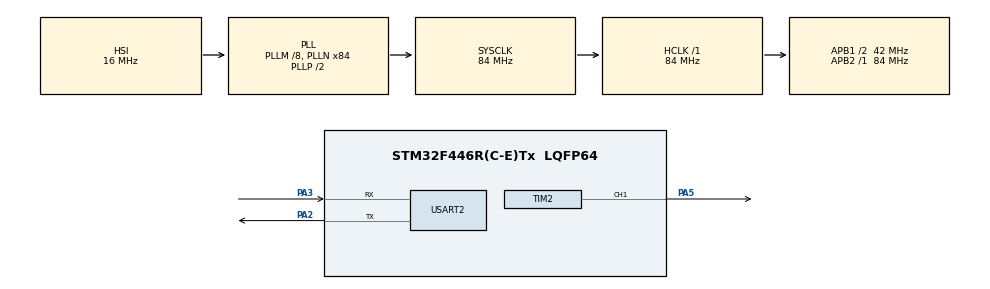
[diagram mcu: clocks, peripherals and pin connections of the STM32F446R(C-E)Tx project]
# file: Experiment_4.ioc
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Mcu.Family=STM32F4
Mcu.Name=STM32F446R(C-E)Tx
Mcu.Package=LQFP64
NVIC.PriorityGroup=NVIC_PRIORITYGROUP_4
PA2.Mode=Asynchronous
PA2.Signal=USART2_TX
PA3.Mode=Asynchronous
PA3.Signal=USART2_RX
PA5.Signal=S_TIM2_CH1_ETR
PC14-OSC32_IN.Mode=LSE-External-Clock-Source
PC14-OSC32_IN.Signal=RCC_OSC32_IN
PC15-OSC32_OUT.Mode=LSE-External-Clock-Source
PC15-OSC32_OUT.Signal=RCC_OSC32_OUT
PH0-OSC_IN.Mode=HSE-External-Clock-Source
PH0-OSC_IN.Signal=RCC_OSC_IN
PH1-OSC_OUT.Mode=HSE-External-Clock-Source
PH1-OSC_OUT.Signal=RCC_OSC_OUT
ProjectManager.HeapSize=0x200
ProjectManager.StackSize=0x400
ProjectManager.TargetToolchain=STM32CubeIDE
RCC.AHBFreq_Value=84000000
RCC.APB1CLKDivider=RCC_HCLK_DIV2
RCC.APB1Freq_Value=42000000
RCC.APB1TimFreq_Value=84000000
RCC.APB2Freq_Value=84000000
RCC.APB2TimFreq_Value=84000000
RCC.CortexFreq_Value=84000000
RCC.HCLKFreq_Value=84000000
RCC.PLLM=8
RCC.PLLN=84
RCC.SYSCLKFreq_VALUE=84000000
RCC.SYSCLKSource=RCC_SYSCLKSOURCE_PLLCLK
RCC.USBFreq_Value=84000000
RCC.VCOOutputFreq_Value=168000000
SH.S_TIM2_CH1_ETR.0=TIM2_CH1,PWM Generation1 CH1
TIM2.Channel-PWM\ Generation1\ CH1=TIM_CHANNEL_1
TIM2.Period=1000
TIM2.Prescaler=840-1
USART2.VirtualMode=VM_ASYNC
board=custom

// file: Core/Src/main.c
/* USER CODE BEGIN Header */
/**
  ******************************************************************************
  * @file           : main.c
  * @brief          : Automotive Status Indicator Main program body
  ******************************************************************************
  * @attention
  *
  * Copyright (c) 2026 STMicroelectronics.
  * All rights reserved.
  *
  * This software is licensed under terms that can be found in the LICENSE file
  * in the root directory of this software component.
  * If no LICENSE file comes with this software, it is provided AS-IS.
  *
  ******************************************************************************
  */
/* USER CODE END Header */

#include "main.h"

/* USER CODE BEGIN Includes */
#include <string.h>
#include <stdio.h>
/* USER CODE END Includes */

TIM_HandleTypeDef htim2;
UART_HandleTypeDef huart2;

/* USER CODE BEGIN PV */
uint8_t rx_data;
uint8_t breathing_enable = 1;
uint8_t ds[] = "Dashboard is Running\r\n";
uint8_t s[]  = "STOP MODE\r\n";
uint8_t r[]  = "RUN MODE\r\n";
/* USER CODE END PV */

void SystemClock_Config(void);
static void MX_GPIO_Init(void);
static void MX_TIM2_Init(void);
static void MX_USART2_UART_Init(void);

int main(void)
{

  /* MCU Configuration--------------------------------------------------------*/

  /* Reset of all peripherals, Initializes the Flash interface and the Systick. */
  HAL_Init();

  /* Configure the system clock */
  SystemClock_Config();

  /* Initialize all configured peripherals */
  MX_GPIO_Init();
  MX_TIM2_Init();
  MX_USART2_UART_Init();

  /* USER CODE BEGIN 2 */

  HAL_TIM_PWM_Start(&htim2, TIM_CHANNEL_1);

  HAL_UART_Transmit(&huart2, (uint8_t*)"DASHBOARD_ACTIVE\r\n", strlen("DASHBOARD_ACTIVE\r\n"), HAL_MAX_DELAY);

  HAL_UART_Receive_IT(&huart2, &rx_data, 1);

  /* USER CODE END 2 */

  /* Infinite loop */
  /* USER CODE BEGIN WHILE */
  while (1){

      HAL_UART_Transmit(&huart2, ds, sizeof(ds), 1000);
      HAL_Delay(1000);

      int x;
      for(x=0; x<1000; x=x+1)
      {
          if(x<=599){
              HAL_UART_Transmit(&huart2, s, sizeof(s), 1000);
              HAL_Delay(5000);
          }
          else{
              HAL_UART_Transmit(&huart2, r, sizeof(r), 1000);
          }
          __HAL_TIM_SET_COMPARE(&htim2, TIM_CHANNEL_1, x);
          HAL_Delay(5);
      }

      for(x=1000; x>0; x=x-1)
      {
          if(x==599){
              HAL_UART_Transmit(&huart2, s, sizeof(s), 1000);
              HAL_Delay(5000);
          }
          else{
              HAL_UART_Transmit(&huart2, r, sizeof(r), 1000);
          }
          __HAL_TIM_SET_COMPARE(&htim2, TIM_CHANNEL_1, x);
          HAL_Delay(1);
      }
  }
  /* USER CODE END WHILE */

}
void SystemClock_Config(void)
{
  RCC_OscInitTypeDef RCC_OscInitStruct = {0};
  RCC_ClkInitTypeDef RCC_ClkInitStruct = {0};

  __HAL_RCC_PWR_CLK_ENABLE();
  __HAL_PWR_VOLTAGESCALING_CONFIG(PWR_REGULATOR_VOLTAGE_SCALE3);

  RCC_OscInitStruct.OscillatorType = RCC_OSCILLATORTYPE_HSI;
  RCC_OscInitStruct.HSIState = RCC_HSI_ON;
  RCC_OscInitStruct.PLL.PLLState = RCC_PLL_ON;
  RCC_OscInitStruct.PLL.PLLSource = RCC_PLLSOURCE_HSI;
  RCC_OscInitStruct.PLL.PLLM = 8;
  RCC_OscInitStruct.PLL.PLLN = 84;
  RCC_OscInitStruct.PLL.PLLP = RCC_PLLP_DIV2;
  RCC_OscInitStruct.PLL.PLLQ = 2;
  RCC_OscInitStruct.PLL.PLLR = 2;
  HAL_RCC_OscConfig(&RCC_OscInitStruct);

  RCC_ClkInitStruct.ClockType = RCC_CLOCKTYPE_HCLK|RCC_CLOCKTYPE_SYSCLK
                              |RCC_CLOCKTYPE_PCLK1|RCC_CLOCKTYPE_PCLK2;
  RCC_ClkInitStruct.SYSCLKSource = RCC_SYSCLKSOURCE_PLLCLK;
  RCC_ClkInitStruct.AHBCLKDivider = RCC_SYSCLK_DIV1;
  RCC_ClkInitStruct.APB1CLKDivider = RCC_HCLK_DIV2;
  RCC_ClkInitStruct.APB2CLKDivider = RCC_HCLK_DIV1;

  HAL_RCC_ClockConfig(&RCC_ClkInitStruct, FLASH_LATENCY_2);
}

static void MX_TIM2_Init(void)
{
  TIM_MasterConfigTypeDef sMasterConfig = {0};
  TIM_OC_InitTypeDef sConfigOC = {0};

  htim2.Instance = TIM2;
  htim2.Init.Prescaler = 84;
  htim2.Init.CounterMode = TIM_COUNTERMODE_UP;
  htim2.Init.Period = 1000;
  htim2.Init.ClockDivision = TIM_CLOCKDIVISION_DIV1;
  HAL_TIM_PWM_Init(&htim2);

  sMasterConfig.MasterOutputTrigger = TIM_TRGO_RESET;
  HAL_TIMEx_MasterConfigSynchronization(&htim2, &sMasterConfig);

  sConfigOC.OCMode = TIM_OCMODE_PWM1;
  sConfigOC.Pulse = 0;
  sConfigOC.OCPolarity = TIM_OCPOLARITY_HIGH;
  HAL_TIM_PWM_ConfigChannel(&htim2, &sConfigOC, TIM_CHANNEL_1);

  HAL_TIM_MspPostInit(&htim2);
}

static void MX_USART2_UART_Init(void)
{
  huart2.Instance = USART2;
  huart2.Init.BaudRate = 115200;
  huart2.Init.WordLength = UART_WORDLENGTH_8B;
  huart2.Init.StopBits = UART_STOPBITS_1;
  huart2.Init.Parity = UART_PARITY_NONE;
  huart2.Init.Mode = UART_MODE_TX_RX;
  HAL_UART_Init(&huart2);
}

static void MX_GPIO_Init(void)
{
  __HAL_RCC_GPIOC_CLK_ENABLE();
  __HAL_RCC_GPIOH_CLK_ENABLE();
  __HAL_RCC_GPIOA_CLK_ENABLE();
}

/* USER CODE BEGIN 4 */

void HAL_UART_RxCpltCallback(UART_HandleTypeDef *huart)
{
  if(huart->Instance == USART2)
  {
    if(rx_data == 'S')
    {
      breathing_enable = 0;
      __HAL_TIM_SET_COMPARE(&htim2, TIM_CHANNEL_1, 600);
    }
    else if(rx_data == 'R')
    {
      breathing_enable = 1;
    }

    HAL_UART_Receive_IT(&huart2, &rx_data, 1);
  }
}

/* USER CODE END 4 */

/**
  * @brief  Error Handler
  */
void Error_Handler(void)
{
  __disable_irq();
  while (1)
  {
  }
}
